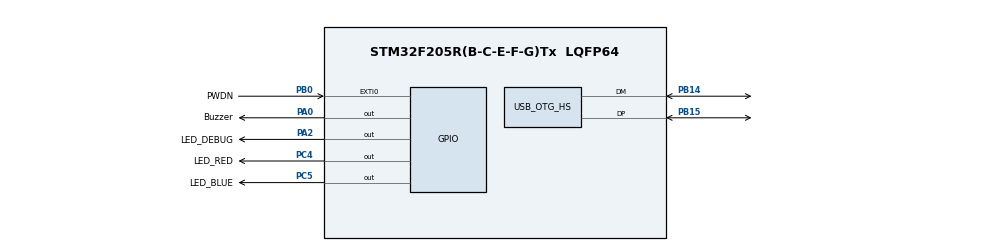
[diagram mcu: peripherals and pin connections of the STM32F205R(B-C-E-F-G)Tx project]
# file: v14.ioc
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Mcu.Family=STM32F2
Mcu.Name=STM32F205R(B-C-E-F-G)Tx
Mcu.Package=LQFP64
NVIC.EXTI0_IRQn=true\:0\:0\:false\:false\:true\:true\:true\:true
NVIC.OTG_HS_EP1_IN_IRQn=true\:0\:0\:false\:false\:true\:true\:true\:true
NVIC.OTG_HS_EP1_OUT_IRQn=true\:0\:0\:false\:false\:true\:true\:true\:true
NVIC.OTG_HS_IRQn=true\:0\:0\:false\:false\:true\:true\:true\:true
NVIC.PriorityGroup=NVIC_PRIORITYGROUP_4
PA0-WKUP.GPIO_Label=Buzzer
PA0-WKUP.Signal=GPIO_Output
PA13.Mode=Serial_Wire
PA13.Signal=SYS_JTMS-SWDIO
PA14.Mode=Serial_Wire
PA14.Signal=SYS_JTCK-SWCLK
PA2.GPIO_Label=LED_DEBUG
PA2.Signal=GPIO_Output
PB0.GPIO_Label=PWDN
PB0.Signal=GPXTI0
PB14.Mode=Device_Only_FS
PB14.Signal=USB_OTG_HS_DM
PB15.Mode=Device_Only_FS
PB15.Signal=USB_OTG_HS_DP
PC4.GPIO_Label=LED_RED
PC4.Signal=GPIO_Output
PC5.GPIO_Label=LED_BLUE
PC5.Signal=GPIO_Output
PH0-OSC_IN.Mode=HSE-External-Oscillator
PH0-OSC_IN.Signal=RCC_OSC_IN
PH1-OSC_OUT.Mode=HSE-External-Oscillator
PH1-OSC_OUT.Signal=RCC_OSC_OUT
ProjectManager.HeapSize=0x2000
ProjectManager.StackSize=0x4000
ProjectManager.TargetToolchain=Makefile
RCC.48MHZClocksFreq_Value=48000000
RCC.AHBFreq_Value=120000000
RCC.APB1CLKDivider=RCC_HCLK_DIV4
RCC.APB1Freq_Value=30000000
RCC.APB1TimFreq_Value=60000000
RCC.APB2CLKDivider=RCC_HCLK_DIV2
RCC.APB2Freq_Value=60000000
RCC.APB2TimFreq_Value=120000000
RCC.CortexFreq_Value=120000000
RCC.HCLKFreq_Value=120000000
RCC.HSE_VALUE=12000000
RCC.HSI_VALUE=16000000
RCC.LSE_VALUE=32768
RCC.PLLM=10
RCC.PLLN=200
RCC.PLLQ=5
RCC.PLLSourceVirtual=RCC_PLLSOURCE_HSE
RCC.SYSCLKFreq_VALUE=120000000
RCC.SYSCLKSource=RCC_SYSCLKSOURCE_PLLCLK
RCC.VCOOutputFreq_Value=240000000
USB_DEVICE.CLASS_NAME_HS=CDC
USB_DEVICE.USBD_DEBUG_LEVEL-CDC_HS=2
USB_DEVICE.VirtualMode-CDC_HS=Cdc
USB_DEVICE.VirtualModeHS=Cdc_HS
USB_OTG_HS.VirtualMode-Device_Only_FS=Device_Only_FS
USB_OTG_HS.dma_enable-Device_Only_FS=ENABLE
USB_OTG_HS.use_dedicated_ep1-Device_Only_FS=DISABLE
VP_USB_DEVICE_VS_USB_DEVICE_CDC_HS.Mode=CDC_HS
board=custom

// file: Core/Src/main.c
/* USER CODE BEGIN Header */
/**
  ******************************************************************************
  * @file           : main.c
  * @brief          : Main program body
  ******************************************************************************
  * @attention
  *
  * Copyright (c) 2025 STMicroelectronics.
  * All rights reserved.
  *
  * This software is licensed under terms that can be found in the LICENSE file
  * in the root directory of this software component.
  * If no LICENSE file comes with this software, it is provided AS-IS.
  *
  ******************************************************************************
  */
/* USER CODE END Header */
#include "main.h"
#include "usb_device.h"
#include "gpio.h"

/* USER CODE BEGIN Includes */
#include "app/application.h"
/* USER CODE END Includes */

void SystemClock_Config(void);

int main(void)
{

  /* MCU Configuration--------------------------------------------------------*/

  /* Reset of all peripherals, Initializes the Flash interface and the Systick. */
  HAL_Init();

  /* Configure the system clock */
  SystemClock_Config();

  /* Initialize all configured peripherals */
  MX_GPIO_Init();
  MX_USB_DEVICE_Init();
  /* USER CODE BEGIN 2 */
  application();
  /* USER CODE END 2 */

  /* Infinite loop */
  while (1)
  {

  }
}

void SystemClock_Config(void)
{
  LL_FLASH_SetLatency(LL_FLASH_LATENCY_3);
  while(LL_FLASH_GetLatency()!= LL_FLASH_LATENCY_3)
  {
  }
  LL_RCC_HSE_Enable();

   /* Wait till HSE is ready */
  while(LL_RCC_HSE_IsReady() != 1)
  {

  }
  LL_RCC_PLL_ConfigDomain_SYS(LL_RCC_PLLSOURCE_HSE, LL_RCC_PLLM_DIV_10, 200, LL_RCC_PLLP_DIV_2);
  LL_RCC_PLL_ConfigDomain_48M(LL_RCC_PLLSOURCE_HSE, LL_RCC_PLLM_DIV_10, 200, LL_RCC_PLLQ_DIV_5);
  LL_RCC_PLL_Enable();

   /* Wait till PLL is ready */
  while(LL_RCC_PLL_IsReady() != 1)
  {

  }
  LL_RCC_SetAHBPrescaler(LL_RCC_SYSCLK_DIV_1);
  LL_RCC_SetAPB1Prescaler(LL_RCC_APB1_DIV_4);
  LL_RCC_SetAPB2Prescaler(LL_RCC_APB2_DIV_2);
  LL_RCC_SetSysClkSource(LL_RCC_SYS_CLKSOURCE_PLL);

   /* Wait till System clock is ready */
  while(LL_RCC_GetSysClkSource() != LL_RCC_SYS_CLKSOURCE_STATUS_PLL)
  {

  }
  LL_SetSystemCoreClock(120000000);

   /* Update the time base */
  if (HAL_InitTick (TICK_INT_PRIORITY) != HAL_OK)
  {
    Error_Handler();
  }
}

void Error_Handler(void)
{
  __disable_irq();
  while (1)
  {
  }
}
